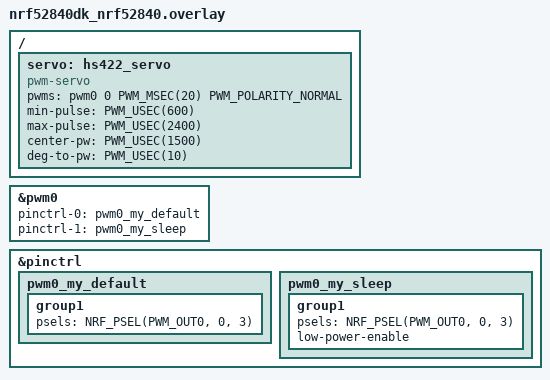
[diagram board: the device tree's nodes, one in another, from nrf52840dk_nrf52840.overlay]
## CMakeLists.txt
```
cmake_minimum_required(VERSION 3.20.0)
find_package(Zephyr REQUIRED HINTS $ENV{ZEPHYR_BASE})

project(lab05-yt1)

target_sources(app PRIVATE src/main.c)
```

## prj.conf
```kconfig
CONFIG_PWM=y
CONFIG_PWM_LOG_LEVEL_ERR=y
CONFIG_LOG=y
```

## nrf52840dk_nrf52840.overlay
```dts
// To get started, press Ctrl+Space to bring up the completion menu and view the available nodes.

// You can also use the buttons in the sidebar to perform actions on nodes.
// Actions currently available include:

// * Enabling / disabling the node
// * Adding the bus to a bus
// * Removing the node
// * Connecting ADC channels

// For more help, browse the DeviceTree documentation at https://docs.zephyrproject.org/latest/guides/dts/index.html
// You can also visit the nRF DeviceTree extension documentation at https://docs.nordicsemi.com/bundle/nrf-connect-vscode/page/guides/ncs_configure_app.html#devicetree-support-in-the-extension

/{
  servo: hs422_servo {
    compatible = "pwm-servo"; // <1>
    pwms = <&pwm0 0 PWM_MSEC(20) PWM_POLARITY_NORMAL>; // <2>
    min-pulse = <PWM_USEC(600)>; // <3>
    max-pulse = <PWM_USEC(2400)>; // <4>
    center-pw = <PWM_USEC(1500)>; // <5>
    deg-to-pw = <PWM_USEC(10)>; // <6>
  };
};

&pwm0 {
  status = "okay"; // <1>
  pinctrl-0 = <&pwm0_my_default>;
  pinctrl-1 = <&pwm0_my_sleep>;
  pinctrl-names = "default", "sleep";
};

&pinctrl {
  pwm0_my_default: pwm0_my_default {
    group1 {
      psels = <NRF_PSEL(PWM_OUT0, 0, 3)>;
    };
  };

  pwm0_my_sleep: pwm0_my_sleep {
    group1 {
      psels = <NRF_PSEL(PWM_OUT0, 0, 3)>;
      low-power-enable; // <5>
    };
  };
};
```

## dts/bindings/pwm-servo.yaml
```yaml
description: PWM-driven servo
compatible: "pwm-servo"
include: base.yaml
properties:
  pwms:
    required: true
    type: phandle-array
    description: PWM specifier driving the servo
  min-pulse:
    required: true
    type: int
    description: Minimum pulse width (nanoseconds)
  max-pulse:
    required: true
    type: int
    description: Maximum pulse width (nanoseconds)
  deg-to-pw:
    required: true
    type: int
    description: Conversion factor from degrees to pulse width (nanoseconds)
  center-pw:
    required: true
    type: int
    description: Pulse width for center position (nanoseconds)
```

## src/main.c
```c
#include <zephyr/kernel.h>
#include <zephyr/drivers/pwm.h>
#include <zephyr/drivers/gpio.h>
#include <zephyr/device.h>
#include <zephyr/devicetree.h>

#define SERVO DT_NODELABEL(servo)
const struct pwm_dt_spec servo = PWM_DT_SPEC_GET(SERVO);
#define PORT0_NI DT_NODELABEL(gpio0)
const struct device *port = DEVICE_DT_GET(PORT0_NI);

#define SERVO_MIN_PULSE_WIDTH DT_PROP(SERVO, min_pulse)
#define SERVO_MAX_PULSE_WIDTH DT_PROP(SERVO, max_pulse)
#define SERVO_CENTER DT_PROP(SERVO, center_pw)
#define SERVO_DEG_CONV DT_PROP(SERVO, deg_to_pw)

/**
 * @brief Convert angle to PWM pulse width
 * 
 * @param angle Servo angle (integer degrees)
 * @return int representing the pulse width (in nanoseconds)
 */
int angle_to_pulsewidth(int angle) {
  int pw = SERVO_CENTER + angle*SERVO_DEG_CONV;
  if (pw < SERVO_MIN_PULSE_WIDTH) {
    pw = SERVO_MIN_PULSE_WIDTH;
  }
  if (pw > SERVO_MAX_PULSE_WIDTH) {
    pw = SERVO_MAX_PULSE_WIDTH;
  }
  return pw;
}

int main(void) {
  gpio_port_value_t pin_values;
  int angle = 0;
  pwm_set_pulse_dt(&servo, angle_to_pulsewidth(angle));
  
  if(device_is_ready(port)) {
    gpio_pin_configure(port, 11, GPIO_INPUT | GPIO_ACTIVE_LOW | GPIO_PULL_UP);
    gpio_pin_configure(port, 12, GPIO_INPUT | GPIO_ACTIVE_LOW | GPIO_PULL_UP);
    gpio_pin_configure(port, 24, GPIO_INPUT | GPIO_ACTIVE_LOW | GPIO_PULL_UP);
    gpio_pin_configure(port, 25, GPIO_INPUT | GPIO_ACTIVE_LOW | GPIO_PULL_UP);
  }
  else return -1;

  while(true) {
    gpio_port_get(port, &pin_values);
    if (angle > 90) angle = 90;
    if (angle < -90) angle = -90;

    if((pin_values & BIT(11))) {
      angle -= 10;
      pwm_set_pulse_dt(&servo, angle_to_pulsewidth(angle));
    }
    if((pin_values & BIT(12))) {
      angle += 10;
      pwm_set_pulse_dt(&servo, angle_to_pulsewidth(angle));
    }
    if((pin_values & BIT(24))) { 
      angle = 0;
      pwm_set_pulse_dt(&servo, angle_to_pulsewidth(angle));
    }
    if((pin_values & BIT(25))) {
      if(angle < 0) {
        angle = -90;
        pwm_set_pulse_dt(&servo, angle_to_pulsewidth(angle));
      }
      else {
        angle = 90;
        pwm_set_pulse_dt(&servo, angle_to_pulsewidth(angle));
      }
    }
    k_msleep(200);
  }
}
```
